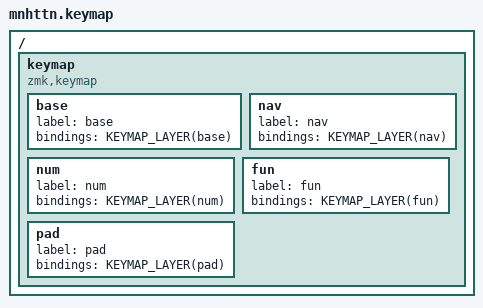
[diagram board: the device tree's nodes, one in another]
/*
 * MNHTTN (fooker) — thin keymap. Split on xiao_ble; vendored shield in
 * boards/shields/mnhttn/. 3x5 core + 3 thumbs/hand (Variant A: outer thumb is the
 * shared 3rd thumb, currently unused). All content lives in config/shared/.
 */

#include <behaviors.dtsi>
#include <dt-bindings/zmk/keys.h>
#include <dt-bindings/zmk/bt.h>
#include <dt-bindings/zmk/outputs.h>

#include "geometry/geom_mnhttn.h"

#include "shared/keys_de.h"
#include "shared/settings.dtsi"
#include "shared/behaviors.dtsi"
#include "shared/macros.dtsi"
#include "shared/combos.dtsi"
#include "shared/core_blocks.dtsi"

/ {
    keymap {
        compatible = "zmk,keymap";

        base { label = "base"; bindings = <KEYMAP_LAYER(base)>; };
        nav  { label = "nav";  bindings = <KEYMAP_LAYER(nav)>;  };
        num  { label = "num";  bindings = <KEYMAP_LAYER(num)>;  };
        fun  { label = "fun";  bindings = <KEYMAP_LAYER(fun)>;  };
        pad  { label = "pad";  bindings = <KEYMAP_LAYER(pad)>;  };
    };
};
